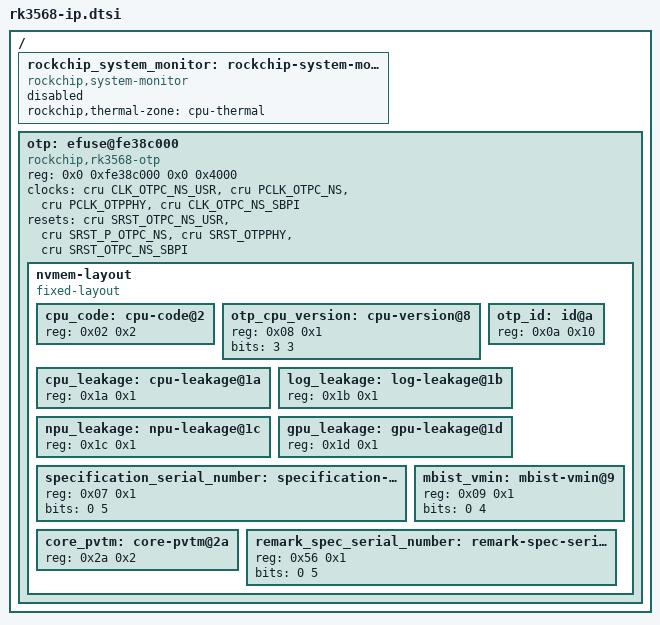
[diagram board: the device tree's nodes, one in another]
/*
 * Copyright (c) 2021 Rockchip Electronics Co., Ltd.
 * Copyright (c) 2025 jjm2473 <jjm2473@gmail.com>
 */

/ {
	rockchip_system_monitor: rockchip-system-monitor {
		compatible = "rockchip,system-monitor";

		rockchip,thermal-zone = "cpu-thermal";
		status = "disabled";
	};

	// upstream, we should remove this node on linux 7.1
	// see https://github.com/torvalds/linux/commit/fae36d252e3344eefd95a94c026c170003805917
	otp: efuse@fe38c000 {
		compatible = "rockchip,rk3568-otp";
		reg = <0x0 0xfe38c000 0x0 0x4000>;
		clocks = <&cru CLK_OTPC_NS_USR>, <&cru PCLK_OTPC_NS>,
			 <&cru PCLK_OTPPHY>, <&cru CLK_OTPC_NS_SBPI>;
		clock-names = "otp", "apb_pclk", "phy", "sbpi";
		resets = <&cru SRST_OTPC_NS_USR>, <&cru SRST_P_OTPC_NS>,
			 <&cru SRST_OTPPHY>, <&cru SRST_OTPC_NS_SBPI>;
		reset-names = "otp", "apb", "phy", "sbpi";

		nvmem-layout {
			compatible = "fixed-layout";
			#address-cells = <1>;
			#size-cells = <1>;

			cpu_code: cpu-code@2 {
				reg = <0x02 0x2>;
			};

			otp_cpu_version: cpu-version@8 {
				reg = <0x08 0x1>;
				bits = <3 3>;
			};

			otp_id: id@a {
				reg = <0x0a 0x10>;
			};

			cpu_leakage: cpu-leakage@1a {
				reg = <0x1a 0x1>;
			};

			log_leakage: log-leakage@1b {
				reg = <0x1b 0x1>;
			};

			npu_leakage: npu-leakage@1c {
				reg = <0x1c 0x1>;
			};

			gpu_leakage: gpu-leakage@1d {
				reg = <0x1d 0x1>;
			};
		};
	};
};

&otp {
	nvmem-layout {
		specification_serial_number: specification-serial-number@7 {
			reg = <0x07 0x1>;
			bits = <0 5>;
		};
		mbist_vmin: mbist-vmin@9 {
			reg = <0x09 0x1>;
			bits = <0 4>;
		};
		core_pvtm:core-pvtm@2a {
			reg = <0x2a 0x2>;
		};
		remark_spec_serial_number: remark-spec-serial-number@56 {
			reg = <0x56 0x1>;
			bits = <0 5>;
		};
	};
};

#include "rk3568-vpu.dtsi"
#include "rk3568-gpu.dtsi"
#include "rk3568-npu.dtsi"
#include "rk3568-crypto.dtsi"
